# max32630 register map
Vendor: Maxim Integrated; Series: max3263x; File version: 1.2
CPU: CM4 r0p1, little endian, no MPU, FPU, 3 interrupt priority bits
Registers are 32-bit, read-write, reset 0x0 unless marked. A register's access mark holds for its fields unless they carry their own. Offsets are from the block's base; [hi:lo] are bit positions.

## SYSMAN — System Manager Settings
Base 0x40000000
0x00 PVT_MONITOR — System Clock Configuration
  [31:0] code — Cryptographic (TPU) Relaxation Oscillator Enable

## RTCTMR — Real Time Clock
Base 0x40000A00
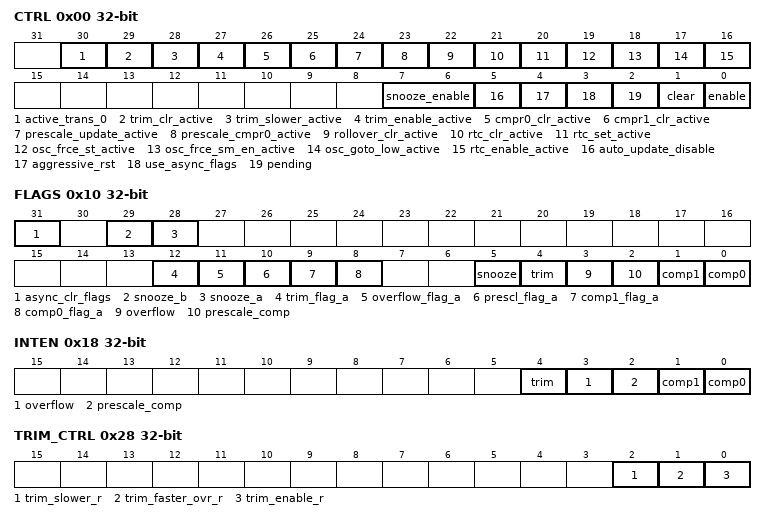
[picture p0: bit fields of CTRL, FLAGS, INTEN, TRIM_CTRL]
0x00 CTRL — RTC Timer Control
  [30] active_trans_0 ro
  [29] trim_clr_active ro
  [28] trim_slower_active ro
  [27] trim_enable_active ro
  [26] cmpr0_clr_active ro
  [25] cmpr1_clr_active ro
  [24] prescale_update_active ro
  [23] prescale_cmpr0_active ro
  [22] rollover_clr_active ro
  [21] rtc_clr_active ro — timer_clr_active
  [20] rtc_set_active ro — timer_set_active
  [19] osc_frce_st_active ro
  [18] osc_frce_sm_en_active ro
  [17] osc_goto_low_active ro
  [16] rtc_enable_active ro — tmr_en_active
  [7:6] snooze_enable
  [5] auto_update_disable
  [4] aggressive_rst — Use Aggressive Reset Mode
  [3] use_async_flags — Use Async RTC Flags
  [2] pending ro — RTC Transaction Pending
  [1] clear wo — RTC Timer Clear Bit
  [0] enable — RTC Timer Enable
0x04 TIMER — RTC Timer Count Value
0x08 COMP0 — RTC Time of Day Alarm 0 Compare Register
0x0C COMP1 — RTC Time of Day Alarm 1 Compare Register
0x10 FLAGS — CPU Interrupt and RTC Domain Flags
  [31] async_clr_flags wo — Asynchronous RTC Flag Clear
  [29] snooze_b wo — Activate RTC Snooze Alarm Mode B
  [28] snooze_a wo — Activate RTC Snooze Alarm Mode A
  [12] trim_flag_a ro — RTC Trim Event 4kHz Flag
  [11] overflow_flag_a ro — RTC Overflow 4kHz Flag
  [10] prescl_flag_a ro — RTC Prescale Compare 4kHz Flag
  [9] comp1_flag_a ro — RTC Compare 1 4kHz Flag
  [8] comp0_flag_a ro — RTC Compare 0 4kHz Flag
  [5] snooze wo — Activate RTC Snooze Alarm
  [4] trim write-1-clears — RTC Trim Interrupt Flag
  [3] overflow write-1-clears — RTC Overflow Interrupt Flag
  [2] prescale_comp write-1-clears — RTC Prescale Compare Int Flag
  [1] comp1 write-1-clears — RTC Compare 1 Interrupt Flag
  [0] comp0 write-1-clears — RTC Compare 0 Interrupt Flag
0x14 SNZ_VAL — RTC Timer Alarm Snooze Value
  [9:0] value — Snooze Value
0x18 INTEN — Interrupt Enable Controls
  [4] trim — RTC Trim Adjust Event Interrupt Enable
  [3] overflow — RTC Overflow Interrupt Enable
  [2] prescale_comp — RTC Prescale Compare Int Enable
  [1] comp1 — RTC Time of Day Alarm (Compare 1) Interrupt Enable
  [0] comp0 — RTC Time of Day Alarm (Compare 0) Interrupt Enable
0x1C PRESCALE — RTC Timer Prescale Setting
  [3:0] prescale
0x24 PRESCALE_MASK — RTC Timer Prescale Compare Mask
  [3:0] prescale_mask
0x28 TRIM_CTRL — RTC Timer Trim Controls
  [2] trim_slower_r ro — RTC Trim Direction Status
  [1] trim_faster_ovr_r — Force RTC Trim to Faster
  [0] trim_enable_r — Enable RTL Trim of RTC Timer
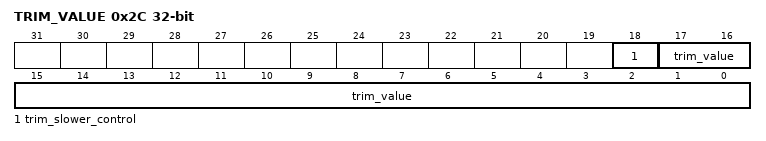
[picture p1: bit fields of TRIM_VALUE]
0x2C TRIM_VALUE — RTC Timer Trim Adjustment Interval
  [18] trim_slower_control — Trim Direction
  [17:0] trim_value — Trim PPM Value

## RTCCFG — Real Time Clock
Base 0x40000A70
0x00 NANO_CNTR — Nano Oscillator Counter Read Register
  [15:0] nanoring_counter ro — Nano Oscillator Counter
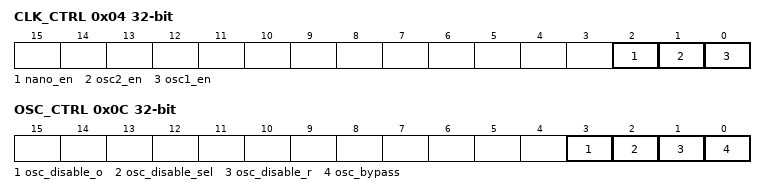
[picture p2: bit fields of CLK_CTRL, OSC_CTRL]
0x04 CLK_CTRL — RTC Clock Control Settings
  [2] nano_en, [1] osc2_en, [0] osc1_en
0x0C OSC_CTRL — RTC Oscillator Control
  [3] osc_disable_o ro, [2] osc_disable_sel, [1] osc_disable_r, [0] osc_bypass

## ICC — Instruction Cache
Base 0x40003000
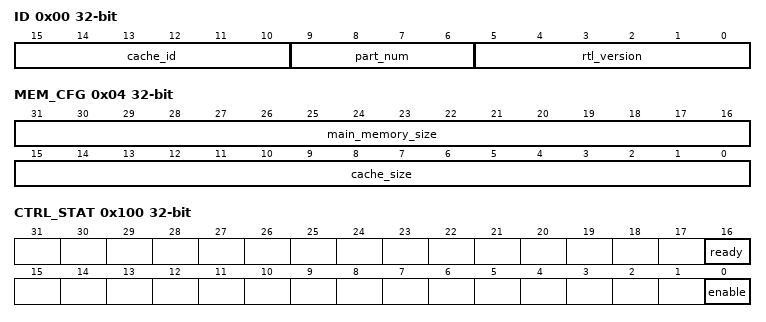
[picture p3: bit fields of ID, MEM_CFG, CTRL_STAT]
0x00 ID — Cache ID Register (INTERNAL USE ONLY)
  [15:10] cache_id ro
  [9:6] part_num ro — Number ID
  [5:0] rtl_version ro — Version
0x04 MEM_CFG — Memory Configuration Register
  [31:16] main_memory_size ro — Internal Flash Memory Size
  [15:0] cache_size ro — Instruction Cache Size
0x100 CTRL_STAT — Control and Status
  [16] ready ro — Cache Ready Status
  [0] enable — Cache Enable
0x700 INVDT_ALL — Invalidate (Clear) Cache Control
